# STM32WL3R register map
File version: 0.3
CPU: CM0+ r0p0, little endian, MPU, no FPU, 4 interrupt priority bits
Registers are 32-bit, read-write, reset 0x0 unless marked. A register's access mark holds for its fields unless they carry their own. Offsets are from the block's base; [hi:lo] are bit positions; {n}, {i} and the like mark numbered series.

## RADIO — RADIO_REG_BLOCK address block description
Base 0x49000000
0x00 RF_FSM0_TIMEOUT
  [7:0] ENA_RFREG_TIMER — Timeout for the RF_REG startup (duration in ENA_RF_REG state)
0x04 RF_FSM1_TIMEOUT reset 0x6
  [7:0] SYNTH_SETUP_TIMER — Timeout management for the RF regulator to stabilize after PLL shut down
0x08 RF_FSM2_TIMEOUT reset 0x50
  [7:0] VCO_CALIB_LOCK_TIMER — Timeout for the PLL calibration + PLL lock (duration in CALIB_VCO+LOCKRXTX state)
0x0C RF_FSM3_TIMEOUT reset 0x28
  [7:0] VCO_LOCK_TIMER — Timeout for the PLL lock event when no calibration is requested (duration in LOCKRXTX state)
0x10 RF_FSM4_TIMEOUT reset 0xF
  [7:0] EN_RX_TIMER — Timeout for the analog RX chain setup (duration in EN_RX state)
0x14 RF_FSM5_TIMEOUT reset 0x19
  [7:0] EN_PA_TIMER — Timeout for the PA setup (duration in EN_PA state)
0x18 RF_FSM6_TIMEOUT reset 0x19
  [7:0] PA_DWN_ANA_TIMER — Timeout for the analog PA (DAC) ramp down (duration in PA_DWN_ANA state)
0x1C RF_FSM7_TIMEOUT reset 0x5
  [7:0] EN_LNA_TIMER — Timeout for LNA enable in the analog RX chain setup (duration in EN_LNA state)
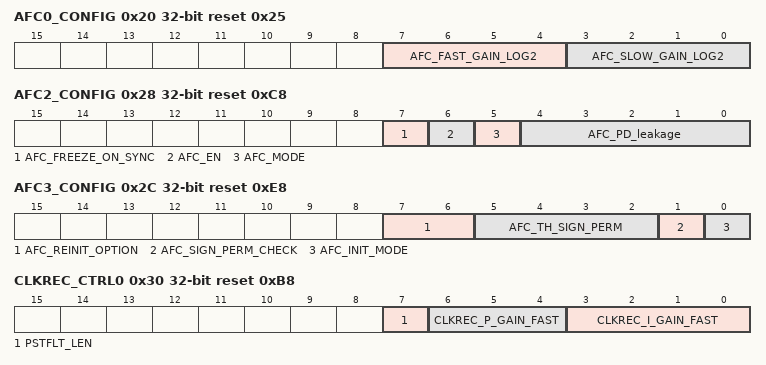
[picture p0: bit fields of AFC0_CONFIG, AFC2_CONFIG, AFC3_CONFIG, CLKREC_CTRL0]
0x20 AFC0_CONFIG reset 0x25
  [7:4] AFC_FAST_GAIN_LOG2 — AFC loop gain in fast mode (2's log)
  [3:0] AFC_SLOW_GAIN_LOG2 — AFC loop gain in slow mode (2's log)
0x24 AFC1_CONFIG reset 0x18
  [7:0] AFC_FAST_PERIOD — Length of the AFC fast period
0x28 AFC2_CONFIG reset 0xC8
  [7] AFC_FREEZE_ON_SYNC — Freeze AFC correction upon sync word detection
  [6] AFC_EN — Enable AFC
  [5] AFC_MODE — Select AFC mode:
  [4:0] AFC_PD_leakage — Length of the AFC fast period
0x2C AFC3_CONFIG reset 0xE8
  [7:6] AFC_REINIT_OPTION — Select the AFC reinitialization option:
  [5:2] AFC_TH_SIGN_PERM — Threshold for the TH sign permanence
  [1] AFC_SIGN_PERM_CHECK — Enable the AFC sign permanent check
  [0] AFC_INIT_MODE — Control the initialization phase of the AFC and clock recovery algorithms:
0x30 CLKREC_CTRL0 reset 0xB8
  [7] PSTFLT_LEN — Post-filter length
  [6:4] CLKREC_P_GAIN_FAST — Clock recovery fast loop gain (log2)
  [3:0] CLKREC_I_GAIN_FAST — Integral fast gain for the clock recovery loop (PLL mode only)
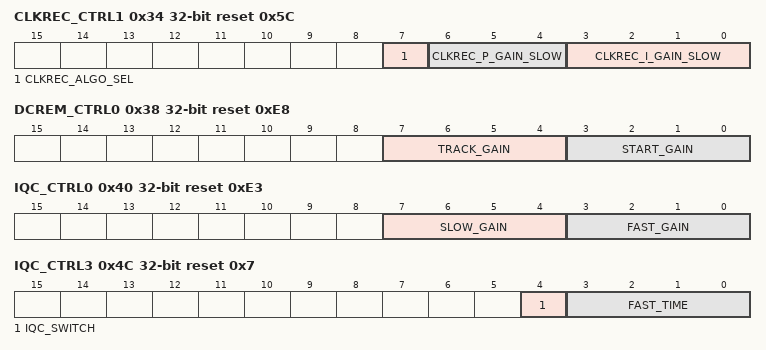
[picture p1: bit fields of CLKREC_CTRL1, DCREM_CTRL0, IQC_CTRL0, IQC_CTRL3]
0x34 CLKREC_CTRL1 reset 0x5C
  [7] CLKREC_ALGO_SEL — Select DLL (0) or PLL (1) mode for the symbol timing recovery
  [6:4] CLKREC_P_GAIN_SLOW — Clock recovery slow loop gain (log2)
  [3:0] CLKREC_I_GAIN_SLOW — Integral slow gain for the clock recovery loop (PLL mode only)
0x38 DCREM_CTRL0 reset 0xE8
  [7:4] TRACK_GAIN — Filter gain in track mode
  [3:0] START_GAIN — Filter gain in start mode
0x3C DCREM_CTRL1 reset 0x5
  [3:0] LN2TIME2SET — Settling time duration
0x40 IQC_CTRL0 reset 0xE3
  [7:4] SLOW_GAIN — Loop gain in slow mode
  [3:0] FAST_GAIN — Loop gain in fast mode
0x44 IQC_CTRL1 reset 0x8
  [7:0] QPD_ATTACK — Attack coefficient for QPD
0x48 IQC_CTRL2 reset 0x8
  [7:0] QPD_DECAY — Decay coefficient for QPD
0x4C IQC_CTRL3 reset 0x7
  [4] IQC_SWITCH — Switch IQ signal components
  [3:0] FAST_TIME — Length of the fast mode
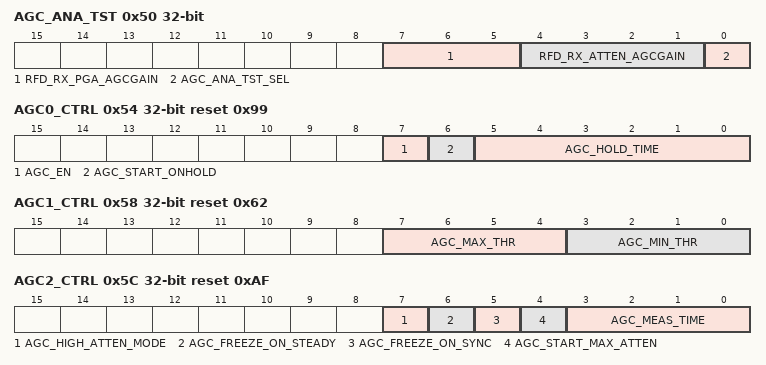
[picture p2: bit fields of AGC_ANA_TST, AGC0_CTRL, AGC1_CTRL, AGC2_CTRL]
0x50 AGC_ANA_TST
  [7:5] RFD_RX_PGA_AGCGAIN — Attenuation at PGA level by step of 6dB with binary code:
  [4:1] RFD_RX_ATTEN_AGCGAIN — Attenuation at LNA level by step of 6dB with thermometric code:
  [0] AGC_ANA_TST_SEL — Select the test mode for AGC analog part:
0x54 AGC0_CTRL reset 0x99
  [7] AGC_EN — Enable the AGC
  [6] AGC_START_ONHOLD — Start the AGC with a hold phase.
  [5:0] AGC_HOLD_TIME
0x58 AGC1_CTRL reset 0x62
  [7:4] AGC_MAX_THR — Maximum signal threshold.
  [3:0] AGC_MIN_THR — Minimum signal threshold.
0x5C AGC2_CTRL reset 0xAF
  [7] AGC_HIGH_ATTEN_MODE — Enable the high attenuation mode.
  [6] AGC_FREEZE_ON_STEADY — Enable the autofreeze feature
  [5] AGC_FREEZE_ON_SYNC — Enable the freeze on SYNC detection feature
  [4] AGC_START_MAX_ATTEN — Start the AGC with maximum attenuation.
  [3:0] AGC_MEAS_TIME — Measure time.
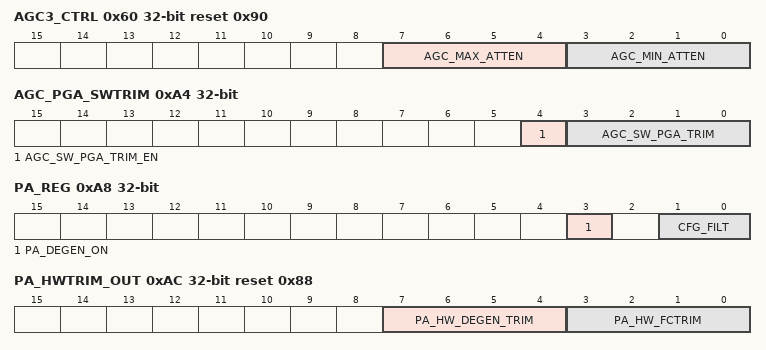
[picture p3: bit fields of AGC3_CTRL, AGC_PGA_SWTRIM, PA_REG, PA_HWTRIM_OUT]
0x60 AGC3_CTRL reset 0x90
  [7:4] AGC_MAX_ATTEN — Maximum AGC attenuation.
  [3:0] AGC_MIN_ATTEN — Minimum AGC attenuation.
0x64 AGC4_CTRL reset 0x2
  [3:0] AGC_FREEZE_THR — Signal threshold for the autofreeze feature.
0x68 AGC_ATTEN0
  [6:0] AGC_ATT_0 — AGC attenuation control setting for step 0
0x6C AGC_ATTEN1 reset 0x10
  [6:0] AGC_ATT_1 — AGC attenuation control setting for step 1
0x70 AGC_ATTEN2 reset 0x20
  [6:0] AGC_ATT_2 — AGC attenuation control setting for step 2
0x74 AGC_ATTEN3 reset 0x30
  [6:0] AGC_ATT_3 — AGC attenuation control setting for step 3
0x78 AGC_ATTEN4 reset 0x40
  [6:0] AGC_ATT_4 — AGC attenuation control setting for step 4
0x7C AGC_ATTEN5 reset 0x41
  [6:0] AGC_ATT_5 — AGC attenuation control setting for step 5
0x80 AGC_ATTEN6 reset 0x43
  [6:0] AGC_ATT_6 — AGC attenuation control setting for step 6
0x84 AGC_ATTEN7 reset 0x47
  [6:0] AGC_ATT_7 — AGC attenuation control setting for step 7
0x88 AGC_ATTEN8 reset 0x4F
  [6:0] AGC_ATT_8 — AGC attenuation control setting for step 8
0x8C AGC_ATTEN9 reset 0x5F
  [6:0] AGC_ATT_9 — AGC attenuation control setting for step 9
{0x8C+4i} AGC{i}_ATTEN_TRIM reset 0xAF (i=1..3)
  [7:0] AGC{i}_ATTEN_TRIM_IN — AGC ATTEN trim[8:1] (calibration in) for step{i} on AGC_ATTEN
0x9C AGC4_ATTEN_TRIM reset 0xAF
  [7:0] AGC4_ATTEN_TRIM_IN — AGC ATTEN trim[8:1] (calibration in) for step4 on AGC_ATTEN.
0xA0 AGC_PGA_HWTRIM_OUT ro reset 0x8
  [3:0] AGC_HW_PGA_TRIM — AGC PGA calibration information loaded by HW.
0xA4 AGC_PGA_SWTRIM
  [4] AGC_SW_PGA_TRIM_EN — Enable overload of PGA HW trim by PGA SW trim provided by AGC_SW_PGA_TRIM bit field
  [3:0] AGC_SW_PGA_TRIM — AGC PGA calibration information provided by SW
0xA8 PA_REG
  [3] PA_DEGEN_ON — Enable a 'degeneration' mode, which introduces a pre-distortion to linearize the power control curve.
  [1:0] CFG_FILT — FIR configuration:
0xAC PA_HWTRIM_OUT ro reset 0x88
  [7:4] PA_HW_DEGEN_TRIM — MSB part meaning:
  [3:0] PA_HW_FCTRIM — PA FC trimming information loaded by HW.
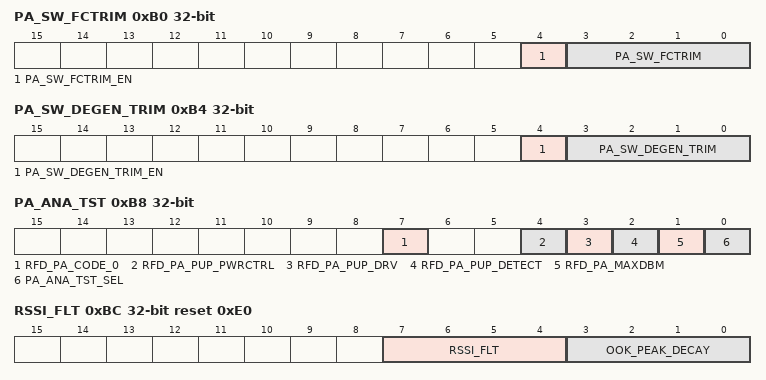
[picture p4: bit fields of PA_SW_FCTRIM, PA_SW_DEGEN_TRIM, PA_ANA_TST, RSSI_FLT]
0xB0 PA_SW_FCTRIM
  [4] PA_SW_FCTRIM_EN — Enable overload of PA HW FC trim by PA SW FC trim provided by PA_HW_FCTRIM bit field
  [3:0] PA_SW_FCTRIM — PA FC trim information provided by SW
0xB4 PA_SW_DEGEN_TRIM
  [4] PA_SW_DEGEN_TRIM_EN — Enable overload of PA HW DEGEN trim by PA SW DEGEN trim provided by PA_HW_FCTRIM bit field
  [3:0] PA_SW_DEGEN_TRIM — PA DEGEN trim information provided by SW
0xB8 PA_ANA_TST
  [7] RFD_PA_CODE_0 — PA_CODE[0] to apply on the analog PA when PA_ANA_TST_SEL bit is set
  [4] RFD_PA_PUP_PWRCTRL — Enable PA gain control.
  [3] RFD_PA_PUP_DRV — Enable PA output stage.
  [2] RFD_PA_PUP_DETECT — Enable of the comparator used to detect if PA is working above the linear region.
  [1] RFD_PA_MAXDBM — Max power delivery enable to apply to RFSUBG RFD_PA_MAXDBM_V12 input when PA_ANA_TST_SEL=1.
  [0] PA_ANA_TST_SEL — Test mode selection:
0xBC RSSI_FLT reset 0xE0
  [7:4] RSSI_FLT — Gain of the RSSI filter
  [3:0] OOK_PEAK_DECAY — Peak decay control for OOK: 3 slow decay; 0 fast decay
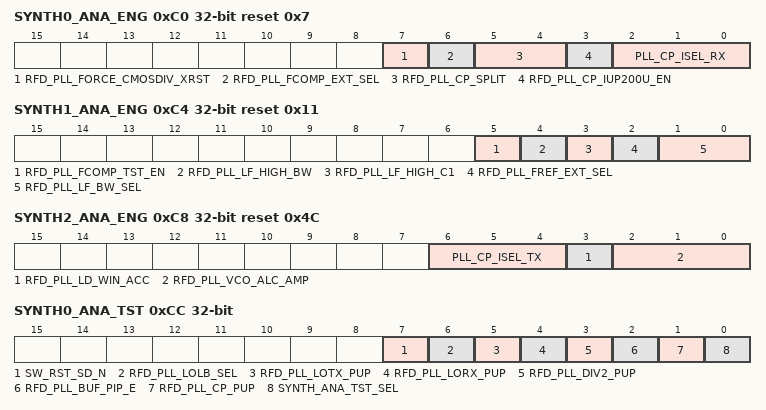
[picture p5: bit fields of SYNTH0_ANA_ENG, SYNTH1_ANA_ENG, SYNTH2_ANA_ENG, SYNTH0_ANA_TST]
0xC0 SYNTH0_ANA_ENG reset 0x7
  [7] RFD_PLL_FORCE_CMOSDIV_XRST — For debug.
  [6] RFD_PLL_FCOMP_EXT_SEL — For debug.
  [5:4] RFD_PLL_CP_SPLIT — Change CP comparator current capability (for debug)
  [3] RFD_PLL_CP_IUP200U_EN — For debug.
  [2:0] PLL_CP_ISEL_RX — Change Charge Pump biasing current configuration for Reception (for debug)
0xC4 SYNTH1_ANA_ENG reset 0x11
  [5] RFD_PLL_FCOMP_TST_EN — Enable the FCOMP_DIV2_TEST signal output on ATB
  [4] RFD_PLL_LF_HIGH_BW — Double Resistor's filter value (for debug)
  [3] RFD_PLL_LF_HIGH_C1 — For debug. PLL-LoopFilter setting (=1 select the maximum value of C1 in loop filter)
  [2] RFD_PLL_FREF_EXT_SEL — For debug.
  [1:0] RFD_PLL_LF_BW_SEL — Resistor filter's bandwidth adjustment (for debug)
0xC8 SYNTH2_ANA_ENG reset 0x4C
  [6:4] PLL_CP_ISEL_TX — Change Charge Pump biasing current configuration for Transmission (for debug)
  [3] RFD_PLL_LD_WIN_ACC — Select the PLL lock detector window selection:
    0=The PLL lock detector uses the largest window =used on cut 1.x; 1=The PLL lock detector uses a smaller window = divided by 2 (default)
  [2:0] RFD_PLL_VCO_ALC_AMP — Select the level of max VCO amplitude in amplitude level control loop.
0xCC SYNTH0_ANA_TST
  [7] SW_RST_SD_N — Control the Sigma Delta reset input when the SYNTH0_ANA_TST[0]=SYNTH_ANA_TST_SEL=1
  [6] RFD_PLL_LOLB_SEL — Control the Low Band selector (when SYNTH_ANA_TST_SEL=1)
  [5] RFD_PLL_LOTX_PUP — Enable of the TX clock buffer 0 (when SYNTH_ANA_TST_SEL=1)
  [4] RFD_PLL_LORX_PUP — Enable of the RX clock buffer 0 (when SYNTH_ANA_TST_SEL=1)
  [3] RFD_PLL_DIV2_PUP — enable of the divider by 2 at VCO output (when SYNTH_ANA_TST_SEL=1)
  [2] RFD_PLL_BUF_PIP_E — Control the PLL loop (0: loop open / 1: loop closed (when SYNTH_ANA_TST_SEL=1)
  [1] RFD_PLL_CP_PUP — Enable of the Charge Pump (when SYNTH_ANA_TST_SEL=1)
  [0] SYNTH_ANA_TST_SEL — Select the test mode for SYNTH0/SYNTH1:
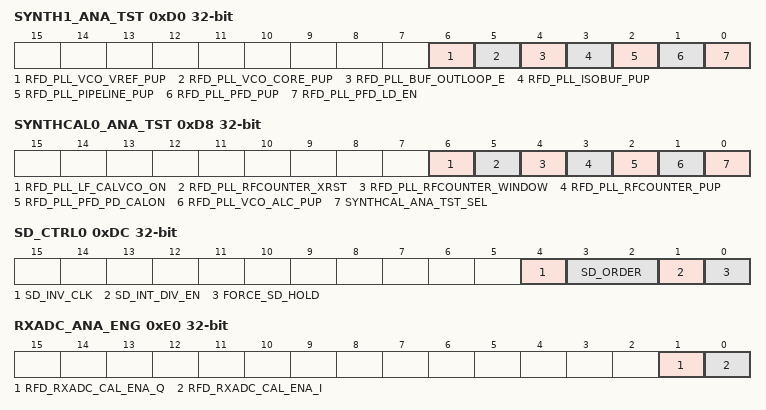
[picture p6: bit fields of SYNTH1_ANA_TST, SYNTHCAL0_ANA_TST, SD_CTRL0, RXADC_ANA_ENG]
0xD0 SYNTH1_ANA_TST
  [6] RFD_PLL_VCO_VREF_PUP — Enable of the VCO voltage ref block (when SYNTH_ANA_TST_SEL=1)
  [5] RFD_PLL_VCO_CORE_PUP — Enable of the VCO_CORE (when SYNTH_ANA_TST_SEL=1)
  [4] RFD_PLL_BUF_OUTLOOP_E — Enable of the VCO_CORE ouput buffer (when SYNTH_ANA_TST_SEL=1)
  [3] RFD_PLL_ISOBUF_PUP — Enable of the enable VCO buffer (when SYNTH_ANA_TST_SEL=1)
  [2] RFD_PLL_PIPELINE_PUP — Enable of the PLL feedback pipeline divider (when SYNTH_ANA_TST_SEL=1)
  [1] RFD_PLL_PFD_PUP — Enable of the phase frequency detector (when SYNTH_ANA_TST_SEL=1)
  [0] RFD_PLL_PFD_LD_EN — Enable of the lock detector emcahnism (when SYNTH_ANA_TST_SEL=1)
0xD4 SYNTHCAL_DIG_ENG
  [7:0] PLL_RFCOUNTER_OFFSET — Control offset of PLL_RFCOUNTER output
0xD8 SYNTHCAL0_ANA_TST
  [6] RFD_PLL_LF_CALVCO_ON — Calibration on going flag on LF (when SYNTH_ANA_TST_SEL=1):
  [5] RFD_PLL_RFCOUNTER_XRST — Reset RF calibration counter:
  [4] RFD_PLL_RFCOUNTER_WINDOW — RF calibration counter window:
  [3] RFD_PLL_RFCOUNTER_PUP — enable RF calibration counter:
  [2] RFD_PLL_PFD_PD_CALON — Stop the phase freq activity for calibration:
  [1] RFD_PLL_VCO_ALC_PUP — Enable of the Charge Pump (when SYNTH_ANA_TST_SEL=1)
  [0] SYNTHCAL_ANA_TST_SEL — Select the test mode for SYNTHCAL:
0xDC SD_CTRL0
  [4] SD_INV_CLK — Change the active edge of the clock sampling the input data
  [3:2] SD_ORDER — Specify the Sigma Delta order
  [1] SD_INT_DIV_EN — Enable the integer operation for the Sigma Delta
  [0] FORCE_SD_HOLD — Hold option for the Sigma Delta
0xE0 RXADC_ANA_ENG
  [1] RFD_RXADC_CAL_ENA_Q — Enable calibration on RX_ADC Q channel
  [0] RFD_RXADC_CAL_ENA_I — Enable calibration on RX_ADC I channel
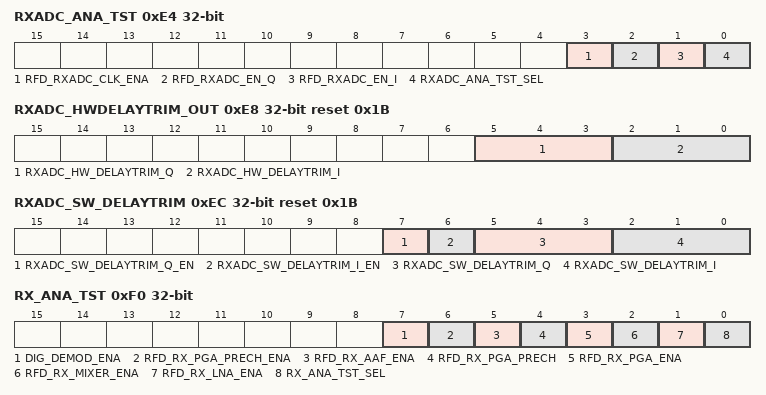
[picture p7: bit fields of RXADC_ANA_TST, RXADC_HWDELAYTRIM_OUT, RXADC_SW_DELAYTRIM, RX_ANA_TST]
0xE4 RXADC_ANA_TST
  [3] RFD_RXADC_CLK_ENA — Enable of the RXADC clock
  [2] RFD_RXADC_EN_Q — Enable of the RXADC Q channel
  [1] RFD_RXADC_EN_I — Enable of the RXADC I channel
  [0] RXADC_ANA_TST_SEL — Select the test mode for RXADC analog part:
0xE8 RXADC_HWDELAYTRIM_OUT ro reset 0x1B
  [5:3] RXADC_HW_DELAYTRIM_Q — Control bits of the RX ADC loop delay for Q channel (provided by the HW trimming in SoC Flash, automatically loaded on POR).
  [2:0] RXADC_HW_DELAYTRIM_I — Control bits of the RX ADC loop delay for I channel (provided by the HW trimming in SoC Flash, automatically loaded on POR)
0xEC RXADC_SW_DELAYTRIM reset 0x1B
  [7] RXADC_SW_DELAYTRIM_Q_EN — Select the SW trim instead of the HW trimmings
  [6] RXADC_SW_DELAYTRIM_I_EN — Select the SW trim instead of the HW trimmings
  [5:3] RXADC_SW_DELAYTRIM_Q — Control bits of the RX ADC loop delay for Q channel, provided by SW
  [2:0] RXADC_SW_DELAYTRIM_I — Control bits of the RX ADC loop delay for I channel, provided by SW
0xF0 RX_ANA_TST
  [7] DIG_DEMOD_ENA — Enable the demodulator:
  [6] RFD_RX_PGA_PRECH_ENA — Enable of the RX PGA precharge
  [5] RFD_RX_AAF_ENA — Enable of the RX AAF
  [4] RFD_RX_PGA_PRECH — Enable of the RX PGA precharge
  [3] RFD_RX_PGA_ENA — Enable of the RX PGA
  [2] RFD_RX_MIXER_ENA — Enable of the RX Mixer
  [1] RFD_RX_LNA_ENA — Enable of the RX LNA
  [0] RX_ANA_TST_SEL — Select the test mode for RX chain analog part:
0xF4 RX_AAF_HWTRIM_OUT ro reset 0x6
  [3:0] AAF_HW_FCTRIM — AAF calibration information loaded by HW.
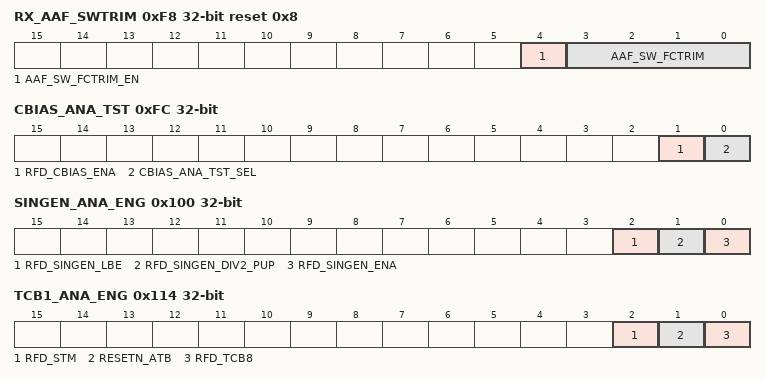
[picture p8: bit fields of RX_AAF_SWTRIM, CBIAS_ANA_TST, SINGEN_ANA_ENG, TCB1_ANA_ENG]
0xF8 RX_AAF_SWTRIM reset 0x8
  [4] AAF_SW_FCTRIM_EN — Select AAF_SW_TRIM[3:0] insead of AAF_HW_TRIM[3:0] info to provide to AAF analog block as calibration value
  [3:0] AAF_SW_FCTRIM — AAF calibration information to provide by SW (supposed to be the result of the AAF calib)
0xFC CBIAS_ANA_TST
  [1] RFD_CBIAS_ENA — Enable signal to apply to RFSUBG RFD_CBIAS_ENA_V12 input when CBIAS_ANA_TST_SEL=1.
  [0] CBIAS_ANA_TST_SEL — Test mode selection:
0x100 SINGEN_ANA_ENG
  [2] RFD_SINGEN_LBE — This bit value is directly connected to the RFSUBG analog IP pin.
  [1] RFD_SINGEN_DIV2_PUP — This bit value is directly connected to the RFSUBG analog IP pin.
  [0] RFD_SINGEN_ENA — Enable SINGEN signal for the RFSUBGanalog IP.
0x104 RFANA_SPARE_IN_ENG
  [7:0] RFANA_SPARE_IN — Spare bits entering directly the RFSUBG analog IP
0x108 RFANA_SPARE_OUT ro reset 0x40
  [7:0] RFANA_SPARE_OUT — Spare bits coming directly from the RFSUBG analog IP
0x10C RFANA_PLL_SPARE_IN
  [7:4] RFANA_PLL_SPARE_IN — Spare bits entering directly the RFSUBG analog IP
0x110 TCB0_ANA_ENG
  [7:0] RFD_TCB7_0 — TCB7_0 control bus (directly connecte to RFSUBG analog IP)
0x114 TCB1_ANA_ENG
  [2] RFD_STM — Analog Self-Test Mode enable
  [1] RESETN_ATB — Active low reset for ATB:
  [0] RFD_TCB8 — TCB_8 control bus (directly connected to RFSUBG analog IP)
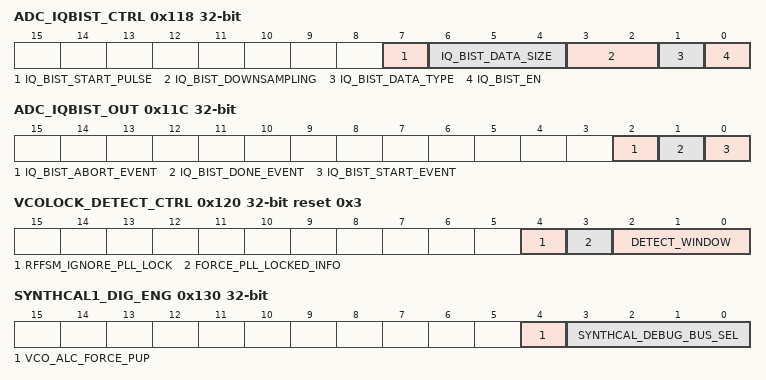
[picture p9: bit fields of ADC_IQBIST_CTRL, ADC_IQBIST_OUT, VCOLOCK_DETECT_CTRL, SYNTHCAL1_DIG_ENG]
0x118 ADC_IQBIST_CTRL
  [7] IQ_BIST_START_PULSE wo — Writing 1 in this bit starts the ADC IQ sampling process.
  [6:4] IQ_BIST_DATA_SIZE — Configure the number of Kbytes to write in RAM before ending an ADC IQ BIST operation:
  [3:2] IQ_BIST_DOWNSAMPLING — Configure the ratio of downsampling to store I/Q samples:
  [1] IQ_BIST_DATA_TYPE — Configure the format of the I/Q sampling storage:
  [0] IQ_BIST_EN — Enable the ADC IQ Bist block:
0x11C ADC_IQBIST_OUT ro
  [2] IQ_BIST_ABORT_EVENT — When set, indicates that the IQ_BIST_EN bit has been cleared or the IQ_BIST_START_PULSE bit has been set to 1 during an active sampling sequence.
  [1] IQ_BIST_DONE_EVENT — When set, indicates that the BIST has finished processing data, according to the IQ_BIST_DATA_SIZE bit field value.
  [0] IQ_BIST_START_EVENT — When set, indicates that a I/Q BIST sequence has started.
0x120 VCOLOCK_DETECT_CTRL reset 0x3
  [4] RFFSM_IGNORE_PLL_LOCK — Information for the Radio FSM to go on sequence despite PLL is not locked.
  [3] FORCE_PLL_LOCKED_INFO — Disable the PLL lock detection and force the PLL lock information high (for debug and test purposes):
  [2:0] DETECT_WINDOW — Define integration window width for lock detection according to formula:
0x124 RF_FSM8_TIMEOUT reset 0xA
  [7:0] SYNTH_PDWN_TIMER — Timeout management for the RF regulator to stabilize after PLL shut down
0x128 RF_FSM9_TIMEOUT reset 0x6
  [7:0] END_RX_TIMER — Timeout management for the RF regulator to stabilize after analog RX chain shut down
0x12C RF_FSM10_TIMEOUT reset 0x6
  [7:0] END_TX_TIMER — Timeout management for the RF regulator to stabilize after clock stop on the analog PA
0x130 SYNTHCAL1_DIG_ENG
  [4] VCO_ALC_FORCE_PUP — Force the enable of the Analog Amplitude Level Control on VCO (debug and test only):
  [3:0] SYNTHCAL_DEBUG_BUS_SEL — Select what is visible in DEBUG_BUS[7:0] in SYNTHCAL_DIG_OUT register
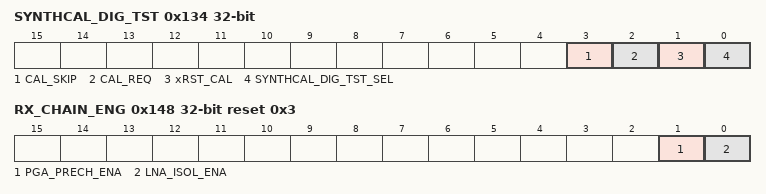
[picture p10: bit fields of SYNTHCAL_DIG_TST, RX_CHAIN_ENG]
0x134 SYNTHCAL_DIG_TST
  [3] CAL_SKIP — Skip the VCO calibration when set (when SYNTHCAL_DIG_TST_SEL=1)
  [2] CAL_REQ — Setting this bit from 0 to 1 starts a VCO calibration (when SYNTHCAL_DIG_TST_SEL=1)
  [1] xRST_CAL — Control the VCO calibrator reset (when SYNTHCAL_DIG_TST_SEL=1).
  [0] SYNTHCAL_DIG_TST_SEL — Test mode selection:
0x138 SYNTHCAL_DIG_OUT ro
  [7:0] SYNTHCAL_DEBUG_BUS — VCO calibration debug bus.
0x13C PA1_ANA_TST
  [7:0] RFD_PA_CODE_8_1 — PA_CODE(8_1) to apply on the analog PA when PA_ANA_TST_SEL bit is set (in PA_ANA_TST register)
0x140 DTB_CONFIG
  [5:0] DTB_CONFIG — DTB configuration selection.
0x144 SUBG_DIG_CTRL0
  [0] FORCE_GPIO_OUTPUT — The direct GPIO signal output option:
0x148 RX_CHAIN_ENG reset 0x3
  [1] PGA_PRECH_ENA — Option for PGA precharge during the EN_RX state of the Radio FSM:
  [0] LNA_ISOL_ENA — Option for LNA during the EN_RX state of the Radio FSM:
0x14C DEMOD_DIG_ENG reset 0x3
  [2:0] RX_BLANKING_LENGTH — Number of data samples at RX start for which the signal at the output of the channel filter is kept forced to zero:
